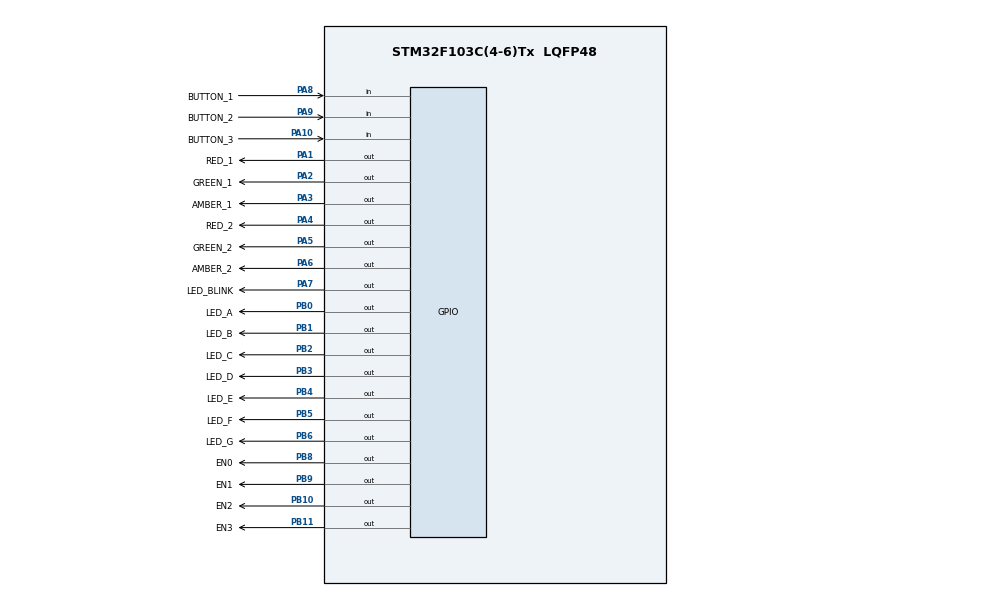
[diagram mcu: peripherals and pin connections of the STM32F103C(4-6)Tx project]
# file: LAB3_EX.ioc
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Mcu.Family=STM32F1
Mcu.Name=STM32F103C(4-6)Tx
Mcu.Package=LQFP48
NVIC.PriorityGroup=NVIC_PRIORITYGROUP_4
NVIC.TIM2_IRQn=true\:0\:0\:false\:false\:true\:true\:true
PA1.GPIO_Label=RED_1
PA1.Signal=GPIO_Output
PA10.GPIO_Label=BUTTON_3
PA10.GPIO_PuPd=GPIO_PULLUP
PA10.Signal=GPIO_Input
PA2.GPIO_Label=GREEN_1
PA2.Signal=GPIO_Output
PA3.GPIO_Label=AMBER_1
PA3.Signal=GPIO_Output
PA4.GPIO_Label=RED_2
PA4.Signal=GPIO_Output
PA5.GPIO_Label=GREEN_2
PA5.Signal=GPIO_Output
PA6.GPIO_Label=AMBER_2
PA6.Signal=GPIO_Output
PA7.GPIO_Label=LED_BLINK
PA7.Signal=GPIO_Output
PA8.GPIO_Label=BUTTON_1
PA8.GPIO_PuPd=GPIO_PULLUP
PA8.Signal=GPIO_Input
PA9.GPIO_Label=BUTTON_2
PA9.GPIO_PuPd=GPIO_PULLUP
PA9.Signal=GPIO_Input
PB0.GPIO_Label=LED_A
PB0.Signal=GPIO_Output
PB1.GPIO_Label=LED_B
PB1.Signal=GPIO_Output
PB10.GPIO_Label=EN2
PB10.Signal=GPIO_Output
PB11.GPIO_Label=EN3
PB11.Signal=GPIO_Output
PB2.GPIO_Label=LED_C
PB2.Signal=GPIO_Output
PB3.GPIO_Label=LED_D
PB3.Signal=GPIO_Output
PB4.GPIO_Label=LED_E
PB4.Signal=GPIO_Output
PB5.GPIO_Label=LED_F
PB5.Signal=GPIO_Output
PB6.GPIO_Label=LED_G
PB6.Signal=GPIO_Output
PB8.GPIO_Label=EN0
PB8.Signal=GPIO_Output
PB9.GPIO_Label=EN1
PB9.Signal=GPIO_Output
ProjectManager.HeapSize=0x200
ProjectManager.StackSize=0x400
ProjectManager.TargetToolchain=STM32CubeIDE
RCC.APB1Freq_Value=8000000
RCC.APB2Freq_Value=8000000
TIM2.Period=9
TIM2.Prescaler=7999
VP_SYS_VS_ND.Mode=No_Debug
VP_TIM2_VS_ClockSourceINT.Mode=Internal
board=custom

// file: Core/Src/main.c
/* USER CODE BEGIN Header */
/**
  ******************************************************************************
  * @file           : main.c
  * @brief          : Main program body
  ******************************************************************************
  * @attention
  *
  * <h2><center>&copy; Copyright (c) 2023 STMicroelectronics.
  * All rights reserved.</center></h2>
  *
  * This software component is licensed by ST under BSD 3-Clause license,
  * the "License"; You may not use this file except in compliance with the
  * License. You may obtain a copy of the License at:
  *                        opensource.org/licenses/BSD-3-Clause
  *
  ******************************************************************************
  */
/* USER CODE END Header */
#include "main.h"

/* USER CODE BEGIN Includes */
#include "global.h"
/* USER CODE END Includes */

TIM_HandleTypeDef htim2;

void SystemClock_Config(void);
static void MX_GPIO_Init(void);
static void MX_TIM2_Init(void);

int main(void)
{

  /* MCU Configuration--------------------------------------------------------*/

  /* Reset of all peripherals, Initializes the Flash interface and the Systick. */
  HAL_Init();

  /* Configure the system clock */
  SystemClock_Config();

  /* Initialize all configured peripherals */
  MX_GPIO_Init();
  MX_TIM2_Init();
  /* USER CODE BEGIN 2 */
  HAL_TIM_Base_Start_IT(&htim2);
  /* USER CODE END 2 */
  traffic_state = INIT;
  init_timer();
  /* Infinite loop */
  while (1)
  {
	  // fsm for update state of traffic_state
	  // as state GR, AR, RG and RA, we update through counter of led 7 SEG
	  // this function also display led7SEG and single led according traffic_state
	  fsm_for_traffic_state();

	  // fsm for reading button 1
	  // update traffic_state once button 1 is pressed or pressed in 1s
	  // and hold this button more than 500ms
	  fsm_for_input_1_processing();

	  // fsm for reading button 3
	  // if traffic_state is MODE2, 3 or 4, it will increase value of traffic_led_7SEG
	  // once pressed or hold button 2 more than 1 second or every 0.5 second after
	  // hold button 2 more than 1 second
	  fsm_for_input_2_processing();

	  // fsm for reading button 3
	  // if traffic_state is MODE2, 3 or 4, it will set value of duration of red, amber or green
	  // according with MODE2, 3 or 4 when we pressed it.
	  fsm_for_input_3_processing();
  }
}

void SystemClock_Config(void)
{
  RCC_OscInitTypeDef RCC_OscInitStruct = {0};
  RCC_ClkInitTypeDef RCC_ClkInitStruct = {0};

  /** Initializes the RCC Oscillators according to the specified parameters
  * in the RCC_OscInitTypeDef structure.
  */
  RCC_OscInitStruct.OscillatorType = RCC_OSCILLATORTYPE_HSI;
  RCC_OscInitStruct.HSIState = RCC_HSI_ON;
  RCC_OscInitStruct.HSICalibrationValue = RCC_HSICALIBRATION_DEFAULT;
  RCC_OscInitStruct.PLL.PLLState = RCC_PLL_NONE;
  if (HAL_RCC_OscConfig(&RCC_OscInitStruct) != HAL_OK)
  {
    Error_Handler();
  }
  /** Initializes the CPU, AHB and APB buses clocks
  */
  RCC_ClkInitStruct.ClockType = RCC_CLOCKTYPE_HCLK|RCC_CLOCKTYPE_SYSCLK
                              |RCC_CLOCKTYPE_PCLK1|RCC_CLOCKTYPE_PCLK2;
  RCC_ClkInitStruct.SYSCLKSource = RCC_SYSCLKSOURCE_HSI;
  RCC_ClkInitStruct.AHBCLKDivider = RCC_SYSCLK_DIV1;
  RCC_ClkInitStruct.APB1CLKDivider = RCC_HCLK_DIV1;
  RCC_ClkInitStruct.APB2CLKDivider = RCC_HCLK_DIV1;

  if (HAL_RCC_ClockConfig(&RCC_ClkInitStruct, FLASH_LATENCY_0) != HAL_OK)
  {
    Error_Handler();
  }
}

static void MX_TIM2_Init(void)
{

  TIM_ClockConfigTypeDef sClockSourceConfig = {0};
  TIM_MasterConfigTypeDef sMasterConfig = {0};

  htim2.Instance = TIM2;
  htim2.Init.Prescaler = 7999;
  htim2.Init.CounterMode = TIM_COUNTERMODE_UP;
  htim2.Init.Period = 9;
  htim2.Init.ClockDivision = TIM_CLOCKDIVISION_DIV1;
  htim2.Init.AutoReloadPreload = TIM_AUTORELOAD_PRELOAD_DISABLE;
  if (HAL_TIM_Base_Init(&htim2) != HAL_OK)
  {
    Error_Handler();
  }
  sClockSourceConfig.ClockSource = TIM_CLOCKSOURCE_INTERNAL;
  if (HAL_TIM_ConfigClockSource(&htim2, &sClockSourceConfig) != HAL_OK)
  {
    Error_Handler();
  }
  sMasterConfig.MasterOutputTrigger = TIM_TRGO_RESET;
  sMasterConfig.MasterSlaveMode = TIM_MASTERSLAVEMODE_DISABLE;
  if (HAL_TIMEx_MasterConfigSynchronization(&htim2, &sMasterConfig) != HAL_OK)
  {
    Error_Handler();
  }
  /* USER CODE BEGIN TIM2_Init 2 */
  // frequency of timer interrupt
  uint32_t TIMER_F = 8000000/((htim2.Init.Prescaler + 1)*(htim2.Init.Period + 1));
  // cycle of timer interrupt with unit is mili second
  TIMER_DURATION = 1000/TIMER_F;//ms
  /* USER CODE END TIM2_Init 2 */

}

static void MX_GPIO_Init(void)
{
  GPIO_InitTypeDef GPIO_InitStruct = {0};

  /* GPIO Ports Clock Enable */
  __HAL_RCC_GPIOA_CLK_ENABLE();
  __HAL_RCC_GPIOB_CLK_ENABLE();

  /*Configure GPIO pin Output Level */
  HAL_GPIO_WritePin(GPIOA, RED_1_Pin|GREEN_1_Pin|AMBER_1_Pin|RED_2_Pin
                          |GREEN_2_Pin|AMBER_2_Pin|LED_BLINK_Pin, GPIO_PIN_RESET);

  /*Configure GPIO pin Output Level */
  HAL_GPIO_WritePin(GPIOB, LED_A_Pin|LED_B_Pin|LED_C_Pin|EN2_Pin
                          |EN3_Pin|LED_D_Pin|LED_E_Pin|LED_F_Pin
                          |LED_G_Pin|EN0_Pin|EN1_Pin, GPIO_PIN_RESET);

  /*Configure GPIO pins : RED_1_Pin GREEN_1_Pin AMBER_1_Pin RED_2_Pin
                           GREEN_2_Pin AMBER_2_Pin LED_BLINK_Pin */
  GPIO_InitStruct.Pin = RED_1_Pin|GREEN_1_Pin|AMBER_1_Pin|RED_2_Pin
                          |GREEN_2_Pin|AMBER_2_Pin|LED_BLINK_Pin;
  GPIO_InitStruct.Mode = GPIO_MODE_OUTPUT_PP;
  GPIO_InitStruct.Pull = GPIO_NOPULL;
  GPIO_InitStruct.Speed = GPIO_SPEED_FREQ_LOW;
  HAL_GPIO_Init(GPIOA, &GPIO_InitStruct);

  /*Configure GPIO pins : LED_A_Pin LED_B_Pin LED_C_Pin EN2_Pin
                           EN3_Pin LED_D_Pin LED_E_Pin LED_F_Pin
                           LED_G_Pin EN0_Pin EN1_Pin */
  GPIO_InitStruct.Pin = LED_A_Pin|LED_B_Pin|LED_C_Pin|EN2_Pin
                          |EN3_Pin|LED_D_Pin|LED_E_Pin|LED_F_Pin
                          |LED_G_Pin|EN0_Pin|EN1_Pin;
  GPIO_InitStruct.Mode = GPIO_MODE_OUTPUT_PP;
  GPIO_InitStruct.Pull = GPIO_NOPULL;
  GPIO_InitStruct.Speed = GPIO_SPEED_FREQ_LOW;
  HAL_GPIO_Init(GPIOB, &GPIO_InitStruct);

  /*Configure GPIO pins : BUTTON_1_Pin BUTTON_2_Pin BUTTON_3_Pin */
  GPIO_InitStruct.Pin = BUTTON_1_Pin|BUTTON_2_Pin|BUTTON_3_Pin;
  GPIO_InitStruct.Mode = GPIO_MODE_INPUT;
  GPIO_InitStruct.Pull = GPIO_PULLUP;
  HAL_GPIO_Init(GPIOA, &GPIO_InitStruct);

}

/* USER CODE BEGIN 4 */
void HAL_TIM_PeriodElapsedCallback(TIM_HandleTypeDef *htim){
	timer_run();
	button_reading();
}
/* USER CODE END 4 */

void Error_Handler(void)
{
  __disable_irq();
  while (1)
  {
  }
}

/************************ (C) COPYRIGHT STMicroelectronics *****END OF FILE****/
